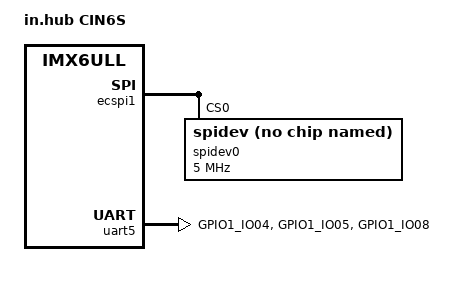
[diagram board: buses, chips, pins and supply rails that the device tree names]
// SPDX-License-Identifier: GPL-2.0-only
/*
 * Copyright 2025 in.hub GmbH
 */

/dts-v1/;

#include "imx6ull-inhub-emmc.dtsi"
#include "imx6ull-inhub-lan8831.dtsi"

/ {
	model = "in.hub CIN6S";
	compatible = "inhub,cin6s", "fsl,imx6ull";
};

/delete-node/ &adc1;

&iomuxc {
	pinctrl-0 = <&pinctrl_gpio2 &pinctrl_gpio3 &pinctrl_gpio4 &pinctrl_gpio6 &pinctrl_usb2_ctrl>;

	/delete-node/ adc1grp;
	/delete-node/ usdhc2grp;
	/delete-node/ uart5grp;

	pinctrl_uart5: uart5grp {
		fsl,pins = <
			MX6UL_PAD_GPIO1_IO04__UART5_DTE_RX	0x1b0b1 /* SODIMM 19 */
			MX6UL_PAD_GPIO1_IO05__UART5_DTE_TX	0x1b0b1 /* SODIMM 21 */
			MX6UL_PAD_GPIO1_IO08__UART5_DTE_CTS	0x1b0b1 /* SODIMM 4 */
		>;
	};

	pinctrl_usb2_ctrl: usb2ctrlgrp {
		fsl,pins = <
			MX6UL_PAD_GPIO1_IO03__GPIO1_IO03 0x000050B0 /* SODIMM 89 */
		>;
	};
};

&ecspi1 {
	status = "okay";

	spidev0: spi@0 {
		compatible = "spidev";
		reg = <0>;
		spi-max-frequency = <5000000>;
	};
};

&uart5 {
	pinctrl-names = "default";
	pinctrl-0 = <&pinctrl_uart5>;
	linux,rs485-enabled-at-boot-time;
	uart-has-rtscts;
	status = "okay";
};
